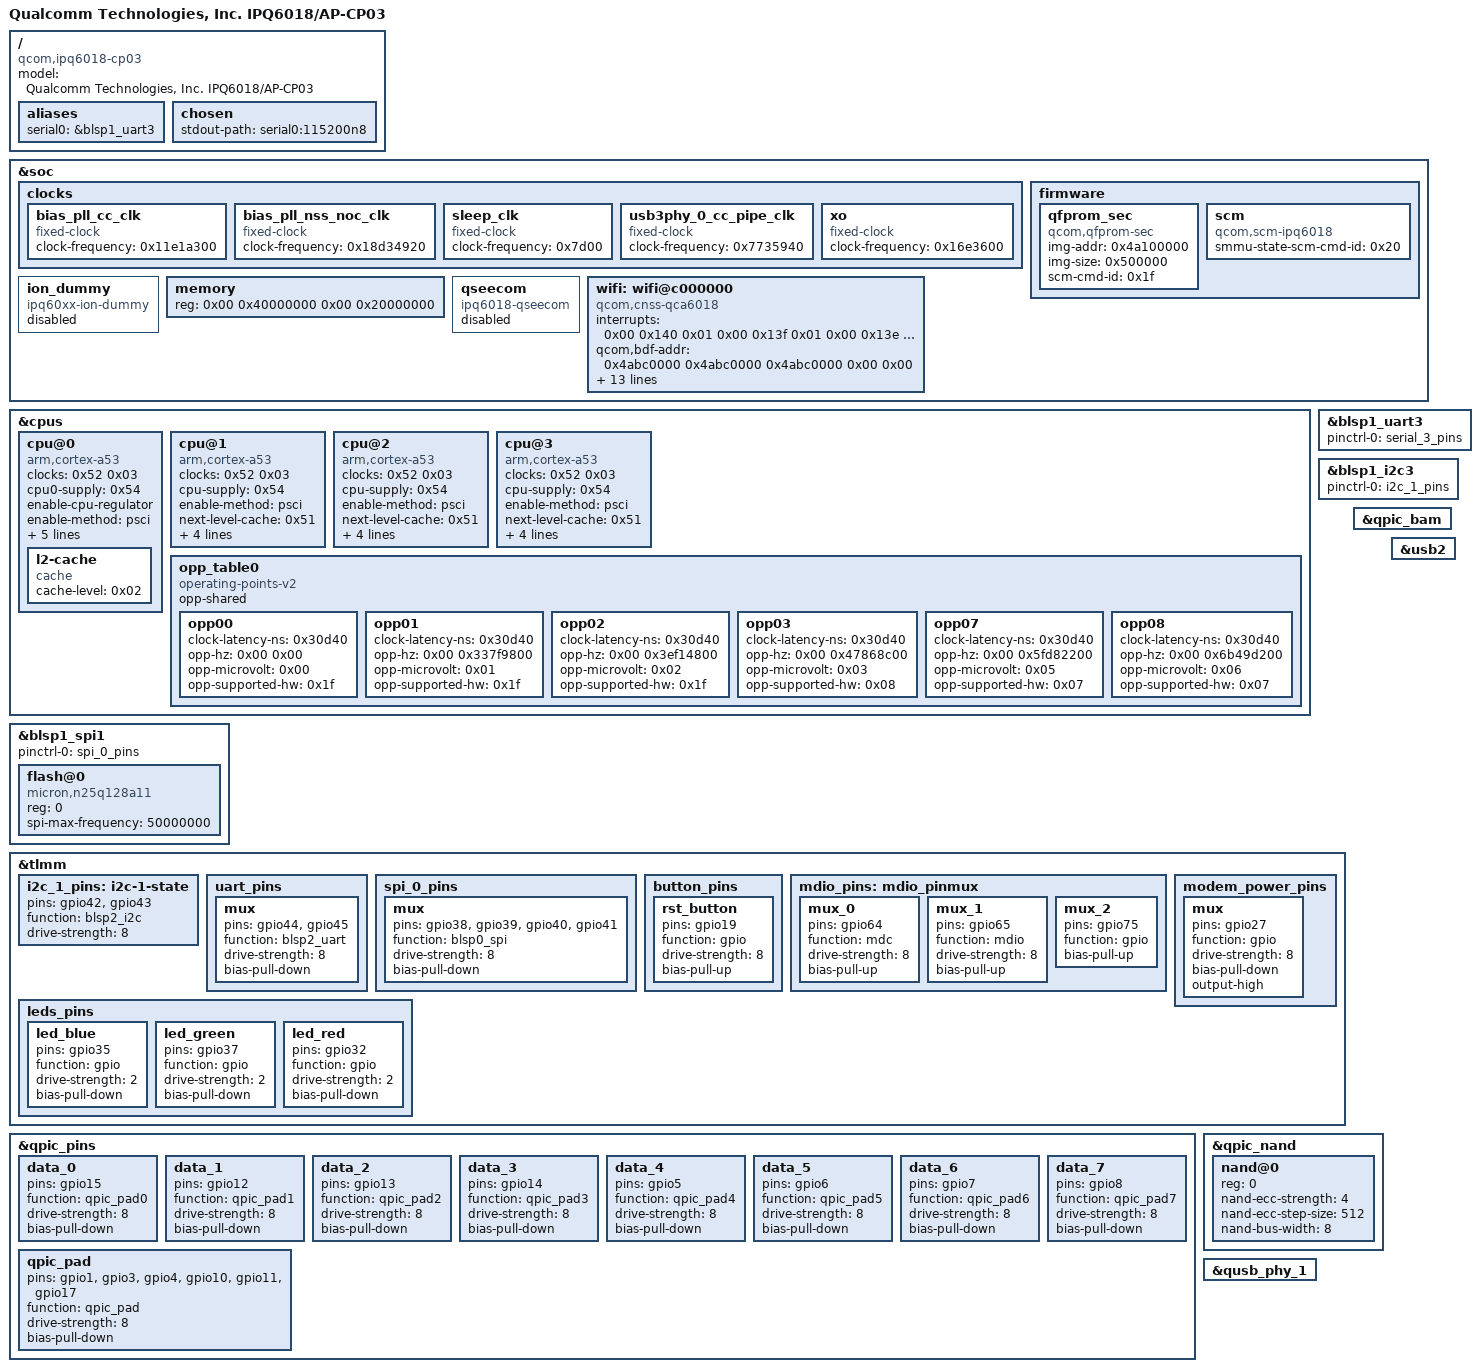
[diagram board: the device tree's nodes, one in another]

// SPDX-License-Identifier: (GPL-2.0+ OR BSD-3-Clause)
/*
 * IPQ6018 CP01 board device tree source
 *
 * Copyright (c) 2019, The Linux Foundation. All rights reserved.
 */
/dts-v1/;
#include "ipq6018-new.dtsi"
/ {
	model = "Qualcomm Technologies, Inc. IPQ6018/AP-CP03";
	compatible = "qcom,ipq6018-cp03", "qcom,ipq6018";
	aliases {
		serial0 = &blsp1_uart3;
	};
	chosen {
		stdout-path = "serial0:115200n8";
	};
};

&soc {

	clocks {

		bias_pll_cc_clk {
			#clock-cells = <0x00>;
			clock-frequency = <0x11e1a300>;
			compatible = "fixed-clock";
		};

		bias_pll_nss_noc_clk {
			#clock-cells = <0x00>;
			clock-frequency = <0x18d34920>;
			compatible = "fixed-clock";
		};

		sleep_clk {
			#clock-cells = <0x00>;
			clock-frequency = <0x7d00>;
			compatible = "fixed-clock";
			linux,phandle = <0x20>;
			phandle = <0x20>;
		};

		usb3phy_0_cc_pipe_clk {
			#clock-cells = <0x00>;
			clock-frequency = <0x7735940>;
			compatible = "fixed-clock";
		};

		xo {
			#clock-cells = <0x00>;
			clock-frequency = <0x16e3600>;
			compatible = "fixed-clock";
		};
	};


	firmware {

		qfprom_sec {
			compatible = "qcom,qfprom-sec";
			img-addr = <0x4a100000>;
			img-size = <0x500000>;
			scm-cmd-id = <0x1f>;
		};

		scm {
			compatible = "qcom,scm-ipq6018";
			smmu-state-scm-cmd-id = <0x20>;
		};
	};

	ion_dummy {
		compatible = "ipq60xx-ion-dummy";
		status = "disabled";
	};

	memory {
		device_type = "memory";
		reg = <0x00 0x40000000 0x00 0x20000000>;
	};

	qseecom {
		compatible = "ipq6018-qseecom";
		status = "disabled";
	};

	wifi: wifi@c000000 {};
};

&cpus {
	#address-cells = <0x01>;
	#size-cells = <0x00>;

	cpu@0 {
		clock-names = "cpu";
		clocks = <0x52 0x03>;
		compatible = "arm,cortex-a53";
		cpu0-supply = <0x54>;
		device_type = "cpu";
		enable-cpu-regulator;
		enable-method = "psci";
		linux,phandle = <0x3e>;
		next-level-cache = <0x51>;
		operating-points-v2 = <0x53>;
		phandle = <0x3e>;
		qcom,acc = <0x50>;
		reg = <0x00>;
		voltage-tolerance = <0x01>;

		l2-cache {
			cache-level = <0x02>;
			compatible = "cache";
			linux,phandle = <0x51>;
			phandle = <0x51>;
		};
	};

	cpu@1 {
		clock-names = "cpu";
		clocks = <0x52 0x03>;
		compatible = "arm,cortex-a53";
		cpu-supply = <0x54>;
		device_type = "cpu";
		enable-method = "psci";
		linux,phandle = <0x40>;
		next-level-cache = <0x51>;
		operating-points-v2 = <0x53>;
		phandle = <0x40>;
		qcom,acc = <0x55>;
		reg = <0x01>;
		voltage-tolerance = <0x01>;
	};

	cpu@2 {
		clock-names = "cpu";
		clocks = <0x52 0x03>;
		compatible = "arm,cortex-a53";
		cpu-supply = <0x54>;
		device_type = "cpu";
		enable-method = "psci";
		linux,phandle = <0x42>;
		next-level-cache = <0x51>;
		operating-points-v2 = <0x53>;
		phandle = <0x42>;
		qcom,acc = <0x56>;
		reg = <0x02>;
		voltage-tolerance = <0x01>;
	};

	cpu@3 {
		clock-names = "cpu";
		clocks = <0x52 0x03>;
		compatible = "arm,cortex-a53";
		cpu-supply = <0x54>;
		device_type = "cpu";
		enable-method = "psci";
		linux,phandle = <0x44>;
		next-level-cache = <0x51>;
		operating-points-v2 = <0x53>;
		phandle = <0x44>;
		qcom,acc = <0x57>;
		reg = <0x03>;
		voltage-tolerance = <0x01>;
	};

	opp_table0 {
		compatible = "operating-points-v2";
		linux,phandle = <0x53>;
		opp-shared;
		phandle = <0x53>;

		opp00 {
			clock-latency-ns = <0x30d40>;
			opp-hz = <0x00 0x00>;
			opp-microvolt = <0x00>;
			opp-supported-hw = <0x1f>;
		};

		opp01 {
			clock-latency-ns = <0x30d40>;
			opp-hz = <0x00 0x337f9800>;
			opp-microvolt = <0x01>;
			opp-supported-hw = <0x1f>;
		};

		opp02 {
			clock-latency-ns = <0x30d40>;
			opp-hz = <0x00 0x3ef14800>;
			opp-microvolt = <0x02>;
			opp-supported-hw = <0x1f>;
		};

		opp03 {
			clock-latency-ns = <0x30d40>;
			opp-hz = <0x00 0x47868c00>;
			opp-microvolt = <0x03>;
			opp-supported-hw = <0x08>;
		};

		opp07 {
			clock-latency-ns = <0x30d40>;
			opp-hz = <0x00 0x5fd82200>;
			opp-microvolt = <0x05>;
			opp-supported-hw = <0x07>;
		};

		opp08 {
			clock-latency-ns = <0x30d40>;
			opp-hz = <0x00 0x6b49d200>;
			opp-microvolt = <0x06>;
			opp-supported-hw = <0x07>;
		};
	};
};



&wifi {
	compatible = "qcom,cnss-qca6018", "qcom,ipq6018-wifi";

	interrupt-names = "misc-pulse1", "misc-latch", "sw-exception","ce0", "ce1", "ce2",
					  "ce3", "ce4", "ce5", "ce6", "ce7", "ce8", "ce9", "ce10", "ce11", "host2wbm-desc-feed",
					  "host2reo-re-injection", "host2reo-command", "host2rxdma-monitor-ring3", "host2rxdma-monitor-ring2",
					  "host2rxdma-monitor-ring1", "reo2ost-exception", "wbm2host-rx-release", "reo2host-status",
					  "reo2host-destination-ring4", "reo2host-destination-ring3", "reo2host-destination-ring2",
					  "reo2host-destination-ring1", "rxdma2host-monitor-destination-mac3", "rxdma2host-monitor-destination-mac2",
					  "rxdma2host-monitor-destination-mac1", "ppdu-end-interrupts-mac3", "ppdu-end-interrupts-mac2",
					  "ppdu-end-interrupts-mac1", "rxdma2host-monitor-status-ring-mac3",
					  "rxdma2host-monitor-status-ring-mac2", "rxdma2host-monitor-status-ring-mac1",
					  "host2rxdma-host-buf-ring-mac3", "host2rxdma-host-buf-ring-mac2",
					  "host2rxdma-host-buf-ring-mac1", "rxdma2host-destination-ring-mac3",
					  "rxdma2host-destination-ring-mac2", "rxdma2host-destination-ring-mac1",
					  "host2tcl-input-ring4", "host2tcl-input-ring3", "host2tcl-input-ring2",
					  "host2tcl-input-ring1", "wbm2host-tx-completions-ring3", "wbm2host-tx-completions-ring2",
					  "wbm2host-tx-completions-ring1", "tcl2host-status-ring",
						"host2tcl-input-ring4", "host2tcl-input-ring3", "host2tcl-input-ring2", 
						"host2tcl-input-ring1", "wbm2host-tx-completions-ring3", "wbm2host-tx-completions-ring2", 
						"wbm2host-tx-completions-ring1", "tcl2host-status-ring";

	interrupts = <0x00 0x140 0x01 0x00 0x13f 0x01 0x00 0x13e 0x01 0x00 0x13c 0x01 0x00 0x13b 0x01 0x00 0x13a 0x01 0x00 0x137 0x01 0x00 0x136 0x01 0x00 0x19b 0x01 0x00 0x19a 0x01 0x00 0x28 0x01 0x00 0x27 0x01 0x00 0x12e 0x01 0x00 0x12d 0x01 0x00 0x25 0x01 0x00 0x24 0x01 0x00 0x128 0x01 0x00 0x127 0x01 0x00 0x126 0x01 0x00 0x125 0x01 0x00 0x124 0x01 0x00 0x123 0x01 0x00 0x122 0x01 0x00 0x121 0x01 0x00 0x120 0x01 0x00 0xef 0x01 0x00 0xec 0x01 0x00 0xeb 0x01 0x00 0xea 0x01 0x00 0xe9 0x01 0x00 0xe8 0x01 0x00 0xe7 0x01 0x00 0xe6 0x01 0x00 0xe5 0x01 0x00 0xe4 0x01 0x00 0xe0 0x01 0x00 0xdf 0x01 0x00 0xcb 0x01 0x00 0xb7 0x01 0x00 0xb4 0x01 0x00 0xb3 0x01 0x00 0xb2 0x01 0x00 0xb1 0x01 0x00 0xb0 0x01 0x00 0xa3 0x01 0x00 0xa2 0x01 0x00 0xa0 0x01 0x00 0x9f 0x01 0x00 0x9e 0x01 0x00 0x9d 0x01 0x00 0x9c 0x01>;
	qcom,bdf-addr = <0x4abc0000 0x4abc0000 0x4abc0000 0x00 0x00>;
	qcom,bt-active-time = <0x18>;
	qcom,bt-priority-time = <0x12>;
	qcom,caldb-addr = <0x4b500000 0x4b500000 0x4b500000 0x00 0x00>;
	qcom,caldb-size = <0x480000>;
	qcom,coex-algo = <0x02>;
	qcom,coex-mode = <0x02>;
	qcom,hw-mode-id = <0x01>;
	qcom,pta-num = <0x00>;
	qcom,pta-priority = <0x80800505>;
	qcom,rproc = <0x25>;
	qcom,tgt-mem-mode = <0x01>;
	reg = <0xc000000 0x1000000>;
	status = "okay";
};


&blsp1_uart3 {
	pinctrl-0 = <&serial_3_pins>;
	pinctrl-names = "default";
	status = "okay";
};
&blsp1_i2c3 {
	pinctrl-0 = <&i2c_1_pins>;
	pinctrl-names = "default";
	status = "okay";
};
&blsp1_spi1 {
	pinctrl-0 = <&spi_0_pins>;
	pinctrl-names = "default";
	status = "okay";
	flash@0 {
		#address-cells = <1>;
		#size-cells = <1>;
		reg = <0>;
		compatible = "micron,n25q128a11", "jedec,spi-nor";
		spi-max-frequency = <50000000>;
	};
};


&tlmm {
	i2c_1_pins: i2c-1-state {
		pins = "gpio42", "gpio43";
		function = "blsp2_i2c";
		drive-strength = <8>;
	};
	uart_pins: uart_pins {
		mux {
			pins = "gpio44", "gpio45";
			function = "blsp2_uart";
			drive-strength = <8>;
			bias-pull-down;
		};
	};

	spi_0_pins: spi_0_pins {
		mux {
			pins = "gpio38", "gpio39", "gpio40", "gpio41";
			function = "blsp0_spi";
			drive-strength = <8>;
			bias-pull-down;
		};
	};

	button_pins: button_pins {
		rst_button {
			pins = "gpio19";
			function = "gpio";
			drive-strength = <8>;
			bias-pull-up;
		};
	};

	mdio_pins: mdio_pinmux {
		mux_0 {
			pins = "gpio64";
			function = "mdc";
			drive-strength = <8>;
			bias-pull-up;
		};

		mux_1 {
			pins = "gpio65";
			function = "mdio";
			drive-strength = <8>;
			bias-pull-up;
		};

		mux_2 {
			pins = "gpio75";
			function = "gpio";
			bias-pull-up;
		};
	};

	modem_power_pins {
		mux {
			pins = "gpio27";
			function = "gpio";
			drive-strength = <8>;
			bias-pull-down;
			output-high;
		};
	};

	leds_pins: leds_pins {
		led_blue {
			pins = "gpio35";
			function = "gpio";
			drive-strength = <2>;
			bias-pull-down;
		};

		led_green {
			pins = "gpio37";
			function = "gpio";
			drive-strength = <2>;
			bias-pull-down;
		};

		led_red {
			pins = "gpio32";
			function = "gpio";
			drive-strength = <2>;
			bias-pull-down;
		};
	};
};

&qpic_pins {
	data_0 {
		pins = "gpio15";
		function = "qpic_pad0";
		drive-strength = <8>;
		bias-pull-down;
	};

	data_1 {
		pins = "gpio12";
		function = "qpic_pad1";
		drive-strength = <8>;
		bias-pull-down;
	};

	data_2 {
		pins = "gpio13";
		function = "qpic_pad2";
		drive-strength = <8>;
		bias-pull-down;
	};

	data_3 {
		pins = "gpio14";
		function = "qpic_pad3";
		drive-strength = <8>;
		bias-pull-down;
	};

	data_4 {
		pins = "gpio5";
		function = "qpic_pad4";
		drive-strength = <8>;
		bias-pull-down;
	};

	data_5 {
		pins = "gpio6";
		function = "qpic_pad5";
		drive-strength = <8>;
		bias-pull-down;
	};

	data_6 {
		pins = "gpio7";
		function = "qpic_pad6";
		drive-strength = <8>;
		bias-pull-down;
	};

	data_7 {
		pins = "gpio8";
		function = "qpic_pad7";
		drive-strength = <8>;
		bias-pull-down;
	};

	qpic_pad {
		pins = "gpio1",  "gpio3",  "gpio4",
			   "gpio10", "gpio11", "gpio17";
		function = "qpic_pad";
		drive-strength = <8>;
		bias-pull-down;
	};
};


&qpic_bam {
	status = "okay";
};
&qpic_nand {
	status = "okay";
	nand@0 {
		reg = <0>;
		nand-ecc-strength = <4>;
		nand-ecc-step-size = <512>;
		nand-bus-width = <8>;
	};
};
&qusb_phy_1 {
	status = "okay";
};
&usb2 {
	status = "okay";
};
